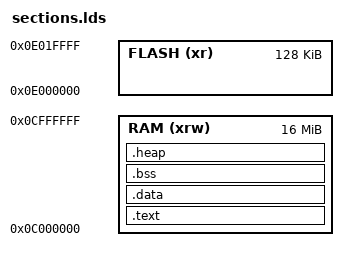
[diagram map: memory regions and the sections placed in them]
/*
This is free and unencumbered software released into the public domain.

Anyone is free to copy, modify, publish, use, compile, sell, or
distribute this software, either in source code form or as a compiled
binary, for any purpose, commercial or non-commercial, and by any
means.
*/

MEMORY
{
    FLASH (xr)  : ORIGIN = 0x0E000000, LENGTH = 0x20000
    RAM (xrw)   : ORIGIN = 0x0C000000, LENGTH = 0x1000000
}


SECTIONS {
    /* The program code and other data goes into RAM */
    .text :
    {
        . = ALIGN(4);
        *(.text)           /* .text sections (code) */
        *(.text*)          /* .text* sections (code) */
        *(.rodata)         /* .rodata sections (constants, strings, etc.) */
        *(.rodata*)        /* .rodata* sections (constants, strings, etc.) */
        *(.srodata)        /* .rodata sections (constants, strings, etc.) */
        *(.srodata*)       /* .rodata* sections (constants, strings, etc.) */
        *(.eh_frame)

        . = ALIGN(4);
        _etext = .;        /* define a global symbol at end of code */
    } >RAM


    .data : 
    {
        . = ALIGN(4);
        _sdata = .;        /* create a global symbol at data start; used by startup code in order to initialise the .data section in RAM */
        _ram_start = .;    /* create a global symbol at ram start for garbage collector */
        . = ALIGN(4);
        *(.data)           /* .data sections */
        *(.data*)          /* .data* sections */
        *(.sdata)           /* .sdata sections */
        *(.sdata*)          /* .sdata* sections */
        . = ALIGN(4);
        _edata = .;        /* define a global symbol at data end; used by startup code in order to initialise the .data section in RAM */
    } >RAM

    /* Uninitialized data section */
    .bss :
    {
        . = ALIGN(4);
        _sbss = .;         /* define a global symbol at bss start; used by startup code */
        *(.bss)
        *(.bss*)
        *(.sbss)
        *(.sbss*)
        *(COMMON)

        . = ALIGN(4);
        _ebss = .;         /* define a global symbol at bss end; used by startup code */
    } >RAM

    /* this is to define the start of the heap, and make sure we have a minimum size */
    .heap :
    {
        . = ALIGN(4);
        _heap_start = .;    /* define a global symbol at heap start */
    } >RAM
}
